# CY8C5868LTI_LP039 register map
File version: 0.1
CY8C58LP
Registers are 8-bit, read-write, no defined reset value unless marked. A register's access mark holds for its fields unless they carry their own. Offsets are from the block's base; lines under a group give offsets from that group; [hi:lo] are bit positions; {n}, {i} and the like mark numbered series; 'fields as' and 'values as' point back to an identical list; <NAME> marks a mode.

## Memory map
0x400043A7 Comp size 0x17F0
0x40004616 ADC size 0x158D — SAR ADC
0x400049C8 psoc size 0x19
0x40006422 Airmar size 0x144 — UART
0x40006447 UART_SBD size 0x11E — UART

## UART_SBD — UART
Base 0x40006447
0x00 TX_UART_SBD_TX_DATA — TX Data Register
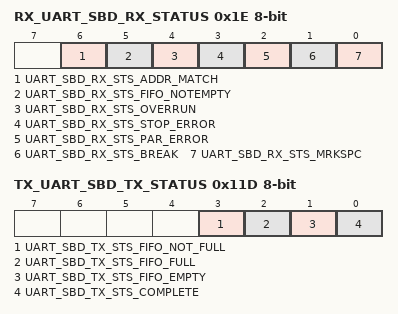
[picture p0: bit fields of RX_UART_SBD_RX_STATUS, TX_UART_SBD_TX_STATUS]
0x1E RX_UART_SBD_RX_STATUS — RX status register
  [6] UART_SBD_RX_STS_ADDR_MATCH ro, [5] UART_SBD_RX_STS_FIFO_NOTEMPTY ro, [4] UART_SBD_RX_STS_OVERRUN ro, [3] UART_SBD_RX_STS_STOP_ERROR ro, [2] UART_SBD_RX_STS_PAR_ERROR ro, [1] UART_SBD_RX_STS_BREAK ro, [0] UART_SBD_RX_STS_MRKSPC ro
0xDE RX_UART_SBD_RX_ADDRESS1 — RX Address1 Register
0xEE RX_UART_SBD_RX_ADDRESS2 — RX Address2 Register
0xFE RX_UART_SBD_RX_DATA — RX Data Register
0x11D TX_UART_SBD_TX_STATUS — TX status register
  [3] UART_SBD_TX_STS_FIFO_NOT_FULL ro, [2] UART_SBD_TX_STS_FIFO_FULL ro, [1] UART_SBD_TX_STS_FIFO_EMPTY ro, [0] UART_SBD_TX_STS_COMPLETE ro

## psoc
Base 0x400049C8
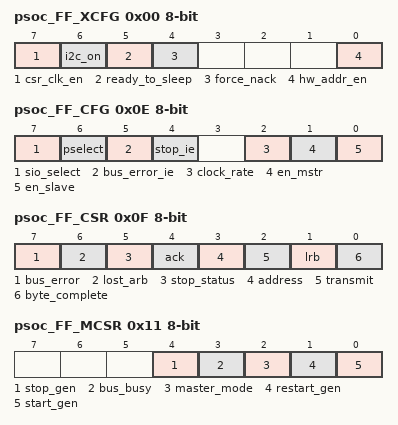
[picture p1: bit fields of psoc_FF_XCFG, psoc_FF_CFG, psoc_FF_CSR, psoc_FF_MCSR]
0x00 psoc_FF_XCFG — Extended Configuration Register: I2C_XCFG
  [7] csr_clk_en, [6] i2c_on, [5] ready_to_sleep ro, [4] force_nack, [0] hw_addr_en
0x02 psoc_FF_ADDR — Slave Adddress Register: I2C_ADR
  [6:0] slave_address — This register holds the slave's 7-bit address.
0x0E psoc_FF_CFG — Configuration Register: I2C_CFG
  [7] sio_select, [6] pselect, [5] bus_error_ie, [4] stop_ie, [2] clock_rate, [1] en_mstr, [0] en_slave
0x0F psoc_FF_CSR — Control and Status Register: I2C_CSR
  [7] bus_error, [6] lost_arb, [5] stop_status, [4] ack, [3] address, [2] transmit, [1] lrb, [0] byte_complete
0x10 psoc_FF_DATA — Data Register: I2C_D
  [7:0] data — This register provides read/write access to the Shift register.
0x11 psoc_FF_MCSR — Master Control and Status Register: I2C_MCSR
  [4] stop_gen, [3] bus_busy ro, [2] master_mode ro, [1] restart_gen, [0] start_gen
0x13 psoc_FF__CLK_DIV1 — Divider of BUS_CLK low part: I2C_CLK_DIV1
  [7:0] Div
0x14 psoc_FF__CLK_DIV2 — Divider high part: I2C_CLK_DIV1
  [1:0] Div
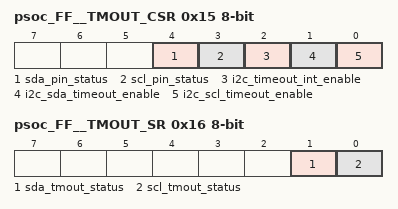
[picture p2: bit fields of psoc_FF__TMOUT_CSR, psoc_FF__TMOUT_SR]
0x15 psoc_FF__TMOUT_CSR — Extended Configuration Register: I2C_TMOUT_CSR
  [4] sda_pin_status, [3] scl_pin_status, [2] i2c_timeout_int_enable ro, [1] i2c_sda_timeout_enable, [0] i2c_scl_timeout_enable
0x16 psoc_FF__TMOUT_SR — Extended Configuration Register: I2C_TMOUT_SR
  [1] sda_tmout_status, [0] scl_tmout_status
0x17 psoc_FF__TMOUT_CFG0 — Extended Configuration Register: TMOUT_CFG0
  [7:0] timeout_period_lowbyte
0x18 psoc_FF__TMOUT_CFG1 — Extended Configuration Register: TMOUT_CFG1
  [3:0] timeout_period_highnibble

## ADC — SAR ADC
Base 0x40004616
0x00 SAR_TR0 — SAR trim register
{0x12F2+i} SAR_CSR{i} (i=0..6) — SAR status and control register {i}
0x1512 SAR_SW0 — SAR Analog Routing Register 0
{0x1512+i} SAR_SW{i} (i=2..4) — SAR Analog Routing Register {i}
0x1518 SAR_SW6 — SAR Analog Routing Register 6
0x1519 SAR_CLK — SAR Clock Selection Register
0x158C SAR_WRK 16-bit — SAR working register

## Airmar — UART
Base 0x40006422
0x00 RX_Airmar_RX_ADDRESS1 — RX Address1 Register
0x10 RX_Airmar_RX_ADDRESS2 — RX Address2 Register
0x20 RX_Airmar_RX_DATA — RX Data Register
0x23 TX_Airmar_TX_DATA — TX Data Register
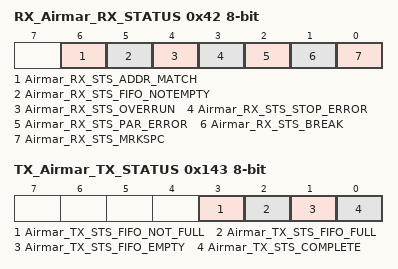
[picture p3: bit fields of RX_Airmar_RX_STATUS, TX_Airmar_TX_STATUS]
0x42 RX_Airmar_RX_STATUS — RX status register
  [6] Airmar_RX_STS_ADDR_MATCH ro, [5] Airmar_RX_STS_FIFO_NOTEMPTY ro, [4] Airmar_RX_STS_OVERRUN ro, [3] Airmar_RX_STS_STOP_ERROR ro, [2] Airmar_RX_STS_PAR_ERROR ro, [1] Airmar_RX_STS_BREAK ro, [0] Airmar_RX_STS_MRKSPC ro
0x143 TX_Airmar_TX_STATUS — TX status register
  [3] Airmar_TX_STS_FIFO_NOT_FULL ro, [2] Airmar_TX_STS_FIFO_FULL ro, [1] Airmar_TX_STS_FIFO_EMPTY ro, [0] Airmar_TX_STS_COMPLETE ro
